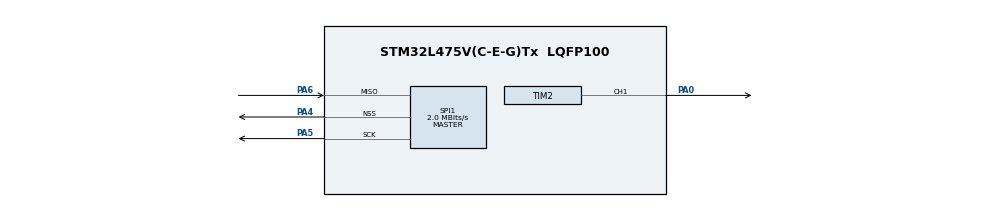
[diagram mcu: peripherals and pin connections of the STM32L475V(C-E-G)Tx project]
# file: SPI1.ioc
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Mcu.Family=STM32L4
Mcu.Name=STM32L475V(C-E-G)Tx
Mcu.Package=LQFP100
NVIC.PriorityGroup=NVIC_PRIORITYGROUP_4
PA0.Signal=S_TIM2_CH1
PA4.Mode=NSS_Signal_Hard_Output
PA4.Signal=SPI1_NSS
PA5.Mode=RX_Only_Simplex_Unidirect_Master
PA5.Signal=SPI1_SCK
PA6.Mode=RX_Only_Simplex_Unidirect_Master
PA6.Signal=SPI1_MISO
ProjectManager.HeapSize=0x200
ProjectManager.StackSize=0x400
ProjectManager.TargetToolchain=TrueSTUDIO
RCC.HSE_VALUE=8000000
RCC.HSI_VALUE=16000000
RCC.LSE_VALUE=32768
RCC.MSI_VALUE=4000000
RCC.VCOOutputFreq_Value=32000000
SH.S_TIM2_CH1.0=TIM2_CH1,PWM Generation1 CH1
SPI1.CalculateBaudRate=2.0 MBits/s
SPI1.Direction=SPI_DIRECTION_2LINES_RXONLY
SPI1.Mode=SPI_MODE_MASTER
SPI1.VirtualNSS=VM_NSSHARD
SPI1.VirtualType=VM_MASTER
TIM2.Channel-PWM\ Generation1\ CH1=TIM_CHANNEL_1
VP_TIM2_VS_ClockSourceINT.Mode=Internal
board=SPI1

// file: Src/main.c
/**
  ******************************************************************************
  * @file           : main.c
  * @brief          : Main program body
  ******************************************************************************
  ** This notice applies to any and all portions of this file
  * that are not between comment pairs USER CODE BEGIN and
  * USER CODE END. Other portions of this file, whether
  * inserted by the user or by software development tools
  * are owned by their respective copyright owners.
  *
  * COPYRIGHT(c) 2018 STMicroelectronics
  *
  * Redistribution and use in source and binary forms, with or without modification,
  * are permitted provided that the following conditions are met:
  *   1. Redistributions of source code must retain the above copyright notice,
  *      this list of conditions and the following disclaimer.
  *   2. Redistributions in binary form must reproduce the above copyright notice,
  *      this list of conditions and the following disclaimer in the documentation
  *      and/or other materials provided with the distribution.
  *   3. Neither the name of STMicroelectronics nor the names of its contributors
  *      may be used to endorse or promote products derived from this software
  *      without specific prior written permission.
  *
  * THIS SOFTWARE IS PROVIDED BY THE COPYRIGHT HOLDERS AND CONTRIBUTORS "AS IS"
  * AND ANY EXPRESS OR IMPLIED WARRANTIES, INCLUDING, BUT NOT LIMITED TO, THE
  * IMPLIED WARRANTIES OF MERCHANTABILITY AND FITNESS FOR A PARTICULAR PURPOSE ARE
  * DISCLAIMED. IN NO EVENT SHALL THE COPYRIGHT HOLDER OR CONTRIBUTORS BE LIABLE
  * FOR ANY DIRECT, INDIRECT, INCIDENTAL, SPECIAL, EXEMPLARY, OR CONSEQUENTIAL
  * DAMAGES (INCLUDING, BUT NOT LIMITED TO, PROCUREMENT OF SUBSTITUTE GOODS OR
  * SERVICES; LOSS OF USE, DATA, OR PROFITS; OR BUSINESS INTERRUPTION) HOWEVER
  * CAUSED AND ON ANY THEORY OF LIABILITY, WHETHER IN CONTRACT, STRICT LIABILITY,
  * OR TORT (INCLUDING NEGLIGENCE OR OTHERWISE) ARISING IN ANY WAY OUT OF THE USE
  * OF THIS SOFTWARE, EVEN IF ADVISED OF THE POSSIBILITY OF SUCH DAMAGE.
  *
  ******************************************************************************
  */
#include "main.h"
#include "stm32l4xx_hal.h"

SPI_HandleTypeDef hspi1;

TIM_HandleTypeDef htim2;

/* USER CODE BEGIN PV */
/* Private variables ---------------------------------------------------------*/

/* USER CODE END PV */

void SystemClock_Config(void);
static void MX_GPIO_Init(void);
static void MX_SPI1_Init(void);
static void MX_TIM2_Init(void);

void HAL_TIM_MspPostInit(TIM_HandleTypeDef *htim);

/* USER CODE BEGIN PFP */
/* Private function prototypes -----------------------------------------------*/

/* USER CODE END PFP */

int main(void)
{

  /* MCU Configuration----------------------------------------------------------*/

  /* Reset of all peripherals, Initializes the Flash interface and the Systick. */
  HAL_Init();

  /* Configure the system clock */
  SystemClock_Config();

  /* Initialize all configured peripherals */
  MX_GPIO_Init();
  MX_SPI1_Init();
  MX_TIM2_Init();
  /* USER CODE BEGIN 2 */
  HAL_TIM_PWM_Start(&htim2, 1);
  /* USER CODE END 2 */

  /* Infinite loop */
  while (1)
  {

  }

}

void SystemClock_Config(void)
{

  RCC_OscInitTypeDef RCC_OscInitStruct;
  RCC_ClkInitTypeDef RCC_ClkInitStruct;

    /**Initializes the CPU, AHB and APB busses clocks
    */
  RCC_OscInitStruct.OscillatorType = RCC_OSCILLATORTYPE_MSI;
  RCC_OscInitStruct.MSIState = RCC_MSI_ON;
  RCC_OscInitStruct.MSICalibrationValue = 0;
  RCC_OscInitStruct.MSIClockRange = RCC_MSIRANGE_6;
  RCC_OscInitStruct.PLL.PLLState = RCC_PLL_NONE;
  if (HAL_RCC_OscConfig(&RCC_OscInitStruct) != HAL_OK)
  {
    _Error_Handler(__FILE__, __LINE__);
  }

    /**Initializes the CPU, AHB and APB busses clocks
    */
  RCC_ClkInitStruct.ClockType = RCC_CLOCKTYPE_HCLK|RCC_CLOCKTYPE_SYSCLK
                              |RCC_CLOCKTYPE_PCLK1|RCC_CLOCKTYPE_PCLK2;
  RCC_ClkInitStruct.SYSCLKSource = RCC_SYSCLKSOURCE_MSI;
  RCC_ClkInitStruct.AHBCLKDivider = RCC_SYSCLK_DIV1;
  RCC_ClkInitStruct.APB1CLKDivider = RCC_HCLK_DIV1;
  RCC_ClkInitStruct.APB2CLKDivider = RCC_HCLK_DIV1;

  if (HAL_RCC_ClockConfig(&RCC_ClkInitStruct, FLASH_LATENCY_0) != HAL_OK)
  {
    _Error_Handler(__FILE__, __LINE__);
  }

    /**Configure the main internal regulator output voltage
    */
  if (HAL_PWREx_ControlVoltageScaling(PWR_REGULATOR_VOLTAGE_SCALE1) != HAL_OK)
  {
    _Error_Handler(__FILE__, __LINE__);
  }

    /**Configure the Systick interrupt time
    */
  HAL_SYSTICK_Config(HAL_RCC_GetHCLKFreq()/1000);

    /**Configure the Systick
    */
  HAL_SYSTICK_CLKSourceConfig(SYSTICK_CLKSOURCE_HCLK);

  /* SysTick_IRQn interrupt configuration */
  HAL_NVIC_SetPriority(SysTick_IRQn, 0, 0);
}

/* SPI1 init function */
static void MX_SPI1_Init(void)
{

  /* SPI1 parameter configuration*/
  hspi1.Instance = SPI1;
  hspi1.Init.Mode = SPI_MODE_MASTER;
  hspi1.Init.Direction = SPI_DIRECTION_2LINES_RXONLY;
  hspi1.Init.DataSize = SPI_DATASIZE_4BIT;
  hspi1.Init.CLKPolarity = SPI_POLARITY_LOW;
  hspi1.Init.CLKPhase = SPI_PHASE_1EDGE;
  hspi1.Init.NSS = SPI_NSS_HARD_OUTPUT;
  hspi1.Init.BaudRatePrescaler = SPI_BAUDRATEPRESCALER_2;
  hspi1.Init.FirstBit = SPI_FIRSTBIT_MSB;
  hspi1.Init.TIMode = SPI_TIMODE_DISABLE;
  hspi1.Init.CRCCalculation = SPI_CRCCALCULATION_DISABLE;
  hspi1.Init.CRCPolynomial = 7;
  hspi1.Init.CRCLength = SPI_CRC_LENGTH_DATASIZE;
  hspi1.Init.NSSPMode = SPI_NSS_PULSE_ENABLE;
  if (HAL_SPI_Init(&hspi1) != HAL_OK)
  {
    _Error_Handler(__FILE__, __LINE__);
  }

}

/* TIM2 init function */
static void MX_TIM2_Init(void)
{

  TIM_ClockConfigTypeDef sClockSourceConfig;
  TIM_MasterConfigTypeDef sMasterConfig;
  TIM_OC_InitTypeDef sConfigOC;

  htim2.Instance = TIM2;
  htim2.Init.Prescaler = 0;
  htim2.Init.CounterMode = TIM_COUNTERMODE_UP;
  htim2.Init.Period = 0xFF;
  htim2.Init.ClockDivision = TIM_CLOCKDIVISION_DIV1;
  htim2.Init.AutoReloadPreload = TIM_AUTORELOAD_PRELOAD_DISABLE;
  if (HAL_TIM_Base_Init(&htim2) != HAL_OK)
  {
    _Error_Handler(__FILE__, __LINE__);
  }

  sClockSourceConfig.ClockSource = TIM_CLOCKSOURCE_INTERNAL;
  if (HAL_TIM_ConfigClockSource(&htim2, &sClockSourceConfig) != HAL_OK)
  {
    _Error_Handler(__FILE__, __LINE__);
  }

  if (HAL_TIM_PWM_Init(&htim2) != HAL_OK)
  {
    _Error_Handler(__FILE__, __LINE__);
  }

  sMasterConfig.MasterOutputTrigger = TIM_TRGO_RESET;
  sMasterConfig.MasterSlaveMode = TIM_MASTERSLAVEMODE_DISABLE;
  if (HAL_TIMEx_MasterConfigSynchronization(&htim2, &sMasterConfig) != HAL_OK)
  {
    _Error_Handler(__FILE__, __LINE__);
  }

  sConfigOC.OCMode = TIM_OCMODE_PWM1;
  sConfigOC.Pulse = 0xFFFF;
  sConfigOC.OCPolarity = TIM_OCPOLARITY_HIGH;
  sConfigOC.OCFastMode = TIM_OCFAST_DISABLE;
  if (HAL_TIM_PWM_ConfigChannel(&htim2, &sConfigOC, TIM_CHANNEL_1) != HAL_OK)
  {
    _Error_Handler(__FILE__, __LINE__);
  }

  HAL_TIM_MspPostInit(&htim2);

}

/** Pinout Configuration
*/
static void MX_GPIO_Init(void)
{

  /* GPIO Ports Clock Enable */
  __HAL_RCC_GPIOA_CLK_ENABLE();

}

void _Error_Handler(char *file, int line)
{
  while(1)
  {
  }
}

/************************ (C) COPYRIGHT STMicroelectronics *****END OF FILE****/
